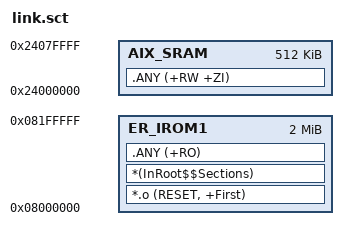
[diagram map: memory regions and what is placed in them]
; *************************************************************
; *** Scatter-Loading Description File generated by uVision ***
; *************************************************************

LR_IROM1 0x08000000 0x00200000  {    ; load region size_region
  ER_IROM1 0x08000000 0x00200000  {  ; load address = execution address
   *.o (RESET, +First)
   *(InRoot$$Sections)
   .ANY (+RO)
  }

  ;ITCM 0X00000000 0X00010000{
  ;  
  ;}
  ;
  ;DTCM 0X20000000 0X00020000{ 
  ;  
  ;}

  AIX_SRAM 0x24000000 0x00080000  {  ; RW data
   .ANY (+RW +ZI)
  }

  ;D2_SRAM1 0X30000000 0X00020000{
  ;  
  ;}
  ;
  ;D2_SRAM2 0X30020000 0X00020000{
  ;
  ;}
  ;
  ;D2_SRAM3 0X30040000 0X00008000{
  ;
  ;}
  ;
  ;D3_SRAM4 0X38000000 0X00008000{
  ;
  ;}
  ;
  ;D3_BACKUP_SRAM 0X38800000 0X00001000{
  ;
  ;}

}



